AUTOSAR XML (schema 4-2-2)
package /Cmu
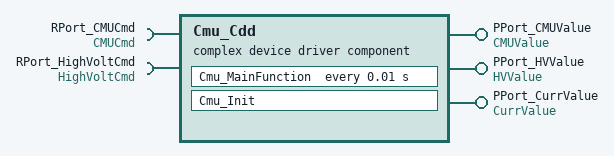
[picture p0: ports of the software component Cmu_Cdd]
  complex device driver sw component type Cmu_Cdd
    provide port PPort_CMUValue: provided-interface=CMUValue
    require port RPort_CMUCmd: required-interface=CMUCmd
    provide port PPort_HVValue: provided-interface=HVValue
    provide port PPort_CurrValue: provided-interface=CurrValue
    require port RPort_HighVoltCmd: required-interface=HighVoltCmd
    behavior SwcInternalBehavior
      timing event TE_Cmu_MainFunction_10ms: start-on-event=Cmu_MainFunction, period=0.01
      runnable Cmu_Init
      runnable Cmu_MainFunction
        data-receive-point-by-arguments:
          access DRPA_CellBalCmd_flg_0: accessed-variable=RPort_CMUCmd.CellBalCmd_flg
          access DRPA_PackVoltMeasCmd_flg_0: accessed-variable=RPort_HighVoltCmd.PackVoltMeasCmd_flg
        data-send-points:
          22 x access:
            DSP_CellBalState_flg_0: accessed-variable=PPort_CMUValue.CellBalState_flg
            DSP_CellTemp1_C_0: accessed-variable=PPort_CMUValue.CellTemp1_C
            DSP_CellTemp1Vld_flg_0: accessed-variable=PPort_CMUValue.CellTemp1Vld_flg
            DSP_CellTemp2_C_0: accessed-variable=PPort_CMUValue.CellTemp2_C
            DSP_CellTemp2Vld_flg_0: accessed-variable=PPort_CMUValue.CellTemp2Vld_flg
            DSP_CMUPCBTemp1_C_0: accessed-variable=PPort_CMUValue.CMUPCBTemp1_C
            DSP_CMUPCBTemp1Vld_flg_0: accessed-variable=PPort_CMUValue.CMUPCBTemp1Vld_flg
            DSP_CMUPCBTemp2_C_0: accessed-variable=PPort_CMUValue.CMUPCBTemp2_C
            DSP_CMUPCBTemp2Vld_flg_0: accessed-variable=PPort_CMUValue.CMUPCBTemp2Vld_flg
            DSP_CellVolt_mV_0: accessed-variable=PPort_CMUValue.CellVolt_mV
            DSP_CellVoltVld_flg_0: accessed-variable=PPort_CMUValue.CellVoltVld_flg
            DSP_CellComErr_flg_0: accessed-variable=PPort_CMUValue.CellComErr_flg
            DSP_CellOpenErr_flg_0: accessed-variable=PPort_CMUValue.CellOpenErr_flg
            DSP_CellMeasCmd_flg_0: accessed-variable=PPort_CMUValue.CellMeasCmd_flg
            DSP_VoltA_V_0: accessed-variable=PPort_HVValue.VoltA_V
            DSP_VoltAVld_flg_0: accessed-variable=PPort_HVValue.VoltAVld_flg
            DSP_VoltB_V_0: accessed-variable=PPort_HVValue.VoltB_V
            DSP_VoltBVld_flg_0: accessed-variable=PPort_HVValue.VoltBVld_flg
            DSP_VoltC_V_0: accessed-variable=PPort_HVValue.VoltC_V
            DSP_VoltCVld_flg_0: accessed-variable=PPort_HVValue.VoltCVld_flg
            DSP_PackCurr_A_0: accessed-variable=PPort_CurrValue.PackCurr_A
            DSP_PackCurrVld_flg_0: accessed-variable=PPort_CurrValue.PackCurrVld_flg
